AUTOSAR XML (schema 4-0-3)
standard types defined: Boolean, UInt16, UInt32, UInt8
package /AUTOSAR_Platform/DataConstrs
  range DC_Boolean: raw 0..1
  range DC_UInt16: raw 0..65535
  range DC_UInt8: raw 0..255
package /PATAC/MSM/ComponentTypes
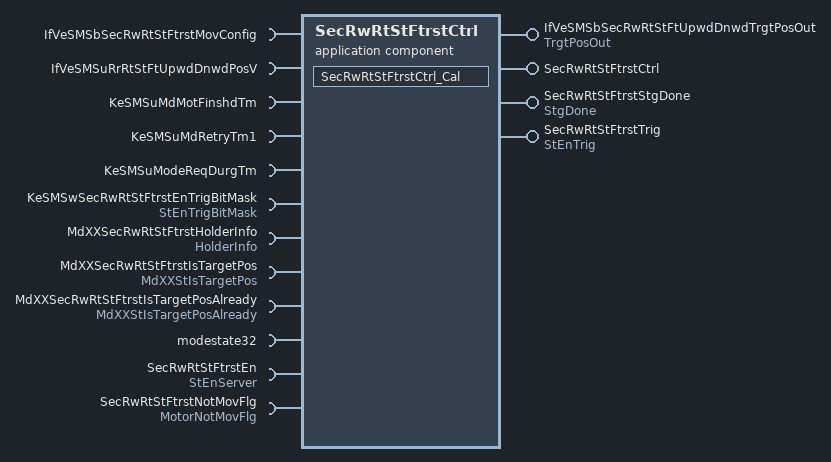
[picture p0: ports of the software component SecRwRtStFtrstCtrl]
  application sw component type SecRwRtStFtrstCtrl
    4 x provide port:
      IfVeSMSbSecRwRtStFtUpwdDnwdTrgtPosOut: nonqueued-sender-com-spec{data-element=TrgtPosOut/Val, init-value=0}, provided-interface=TrgtPosOut
      SecRwRtStFtrstCtrl: server-com-spec{operation=Cal, queue-length=1}, provided-interface=SecRwRtStFtrstCtrl
      SecRwRtStFtrstStgDone: nonqueued-sender-com-spec{data-element=StgDone/Val, init-value=0}, provided-interface=StgDone
      SecRwRtStFtrstTrig: nonqueued-sender-com-spec{data-element=StEnTrig/Val, init-value=0}, provided-interface=StEnTrig
    12 x require port:
      IfVeSMSbSecRwRtStFtrstMovConfig: nonqueued-receiver-com-spec{data-element=IfVeSMSbSecRwRtStFtrstMovConfig/Val, filter=data-filter-type=ALWAYS, init-value=0}, required-interface=IfVeSMSbSecRwRtStFtrstMovConfig
      IfVeSMSuRrRtStFtUpwdDnwdPosV: nonqueued-receiver-com-spec{data-element=IfVeSMSuRrRtStFtUpwdDnwdPosV/Val, filter=data-filter-type=ALWAYS, init-value=0}, required-interface=IfVeSMSuRrRtStFtUpwdDnwdPosV
      KeSMSuMdMotFinshdTm: parameter-require-com-spec{init-value=0, parameter=KeSMSuMdMotFinshdTm/Val}, required-interface=KeSMSuMdMotFinshdTm
      KeSMSuMdRetryTm1: parameter-require-com-spec{init-value=0, parameter=KeSMSuMdRetryTm1/Val}, required-interface=KeSMSuMdRetryTm1
      KeSMSuModeReqDurgTm: parameter-require-com-spec{init-value=0, parameter=KeSMSuModeReqDurgTm/Val}, required-interface=KeSMSuModeReqDurgTm
      KeSMSwSecRwRtStFtrstEnTrigBitMask: parameter-require-com-spec{init-value=6153, parameter=StEnTrigBitMask/Val}, required-interface=StEnTrigBitMask
      MdXXSecRwRtStFtrstHolderInfo: nonqueued-receiver-com-spec{data-element=HolderInfo/Val, filter=data-filter-type=ALWAYS, init-value=0}, required-interface=HolderInfo
      MdXXSecRwRtStFtrstIsTargetPos: nonqueued-receiver-com-spec{data-element=MdXXStIsTargetPos/Val, filter=data-filter-type=ALWAYS, init-value=0}, required-interface=MdXXStIsTargetPos
      MdXXSecRwRtStFtrstIsTargetPosAlready: nonqueued-receiver-com-spec{data-element=MdXXStIsTargetPosAlready/Val, filter=data-filter-type=ALWAYS, init-value=0}, required-interface=MdXXStIsTargetPosAlready
      modestate32: nonqueued-receiver-com-spec{data-element=modestate32/Val, filter=data-filter-type=ALWAYS, init-value=0}, required-interface=modestate32
      SecRwRtStFtrstEn: required-com-specs=[Clear, Get, Set], required-interface=StEnServer
      SecRwRtStFtrstNotMovFlg: nonqueued-receiver-com-spec{data-element=MotorNotMovFlg/Val, filter=data-filter-type=ALWAYS, init-value=0}, required-interface=MotorNotMovFlg
    behavior SecRwRtStFtrstCtrl_InternalBehavior
      operation invoked event OIT_SecRwRtStFtrstCtrl_Cal_SecRwRtStFtrstCtrl_Cal: start-on-event=SecRwRtStFtrstCtrl_Cal, operation=SecRwRtStFtrstCtrl.Cal
      runnable SecRwRtStFtrstCtrl_Cal
        data-receive-point-by-arguments:
          7 x access:
            REC_IfVeSMSbSecRwRtStFtrstMovConfig_Val: accessed-variable=IfVeSMSbSecRwRtStFtrstMovConfig.Val
            REC_IfVeSMSuRrRtStFtUpwdDnwdPosV_Val: accessed-variable=IfVeSMSuRrRtStFtUpwdDnwdPosV.Val
            REC_MdXXSecRwRtStFtrstHolderInfo_Val: accessed-variable=MdXXSecRwRtStFtrstHolderInfo.Val
            REC_MdXXSecRwRtStFtrstIsTargetPos_Val: accessed-variable=MdXXSecRwRtStFtrstIsTargetPos.Val
            REC_MdXXSecRwRtStFtrstIsTargetPosAlready_Val: accessed-variable=MdXXSecRwRtStFtrstIsTargetPosAlready.Val
            REC_modestate32_Val: accessed-variable=modestate32.Val
            REC_SecRwRtStFtrstNotMovFlg_Val: accessed-variable=SecRwRtStFtrstNotMovFlg.Val
        data-send-points:
          access SEND_IfVeSMSbSecRwRtStFtUpwdDnwdTrgtPosOut_Val: accessed-variable=IfVeSMSbSecRwRtStFtUpwdDnwdTrgtPosOut.Val
          access SEND_SecRwRtStFtrstStgDone_Val: accessed-variable=SecRwRtStFtrstStgDone.Val
          access SEND_SecRwRtStFtrstTrig_Val: accessed-variable=SecRwRtStFtrstTrig.Val
        4 x parameter access:
          PA_KeSMSuMdMotFinshdTm_Val: accessed-parameter=KeSMSuMdMotFinshdTm.Val
          PA_KeSMSuMdRetryTm1_Val: accessed-parameter=KeSMSuMdRetryTm1.Val
          PA_KeSMSuModeReqDurgTm_Val: accessed-parameter=KeSMSuModeReqDurgTm.Val
          PA_KeSMSwSecRwRtStFtrstEnTrigBitMask_Val: accessed-parameter=KeSMSwSecRwRtStFtrstEnTrigBitMask.Val
        sync call SC_SecRwRtStFtrstEn_Get: operation=SecRwRtStFtrstEn.Get, timeout=0
  swc implementation SecRwRtStFtrstCtrl_Implementation: behavior=SecRwRtStFtrstCtrl_InternalBehavior
    code-descriptors:
      code Default: artifact-descriptors=autosar-engineering-object={short-label=Default, category=SWSRC}
package /PATAC/MSM/ModeAdjust/CalPortInterface
  parameter interface KeSMSuMdMotFinshdTm
    parameter data prototype Val: sw-calibration-access=READ-WRITE, type=UInt16
  parameter interface KeSMSuModeReqDurgTm
    parameter data prototype Val: sw-calibration-access=READ-WRITE, type=UInt16
  parameter interface StEnTrigBitMask
    parameter data prototype Val: sw-calibration-access=READ-WRITE, type=UInt32
package /PATAC/MSM/ModeAdjust/PortInterface
  client server interface SecRwRtStFtrstCtrl
    operation Cal
  client server interface StEnServer
    operation Clear
      arg data: type=UInt8, direction=IN, server-argument-impl-policy=USE-ARGUMENT-TYPE
    operation Get
      arg data: type=UInt32, direction=OUT, server-argument-impl-policy=USE-ARGUMENT-TYPE
    operation Set
      arg data: type=UInt8, direction=IN, server-argument-impl-policy=USE-ARGUMENT-TYPE
  9 x sender receiver interface:
    HolderInfo: invalidation-policy{data-element=HolderInfo/Val, handle-invalid=DONT-INVALIDATE}
      data Val: type=UInt32
    IfVeSMSbSecRwRtStFtrstMovConfig: invalidation-policy{data-element=IfVeSMSbSecRwRtStFtrstMovConfig/Val, handle-invalid=DONT-INVALIDATE}
      data Val: type=Boolean
    MdXXStIsTargetPos: invalidation-policy{data-element=MdXXStIsTargetPos/Val, handle-invalid=DONT-INVALIDATE}
      data Val: type=UInt32
    MdXXStIsTargetPosAlready: invalidation-policy{data-element=MdXXStIsTargetPosAlready/Val, handle-invalid=DONT-INVALIDATE}
      data Val: type=UInt32
    modestate32: invalidation-policy{data-element=modestate32/Val, handle-invalid=DONT-INVALIDATE}
      data Val: type=UInt32
    MotorNotMovFlg: invalidation-policy{data-element=MotorNotMovFlg/Val, handle-invalid=DONT-INVALIDATE}
      data Val: type=Boolean
    StEnTrig: invalidation-policy{data-element=StEnTrig/Val, handle-invalid=DONT-INVALIDATE}
      data Val: type=Boolean
    StgDone: invalidation-policy{data-element=StgDone/Val, handle-invalid=DONT-INVALIDATE}
      data Val: type=Boolean
    TrgtPosOut: invalidation-policy{data-element=TrgtPosOut/Val, handle-invalid=DONT-INVALIDATE}
      data Val: type=Boolean
package /PATAC/MSM/PortInterfaces
  parameter interface KeSMSuMdRetryTm1
    parameter data prototype Val: sw-calibration-access=READ-WRITE, type=UInt8
  sender receiver interface IfVeSMSuRrRtStFtUpwdDnwdPosV: invalidation-policy{data-element=IfVeSMSuRrRtStFtUpwdDnwdPosV/Val, handle-invalid=DONT-INVALIDATE}
    data Val: type=Boolean
